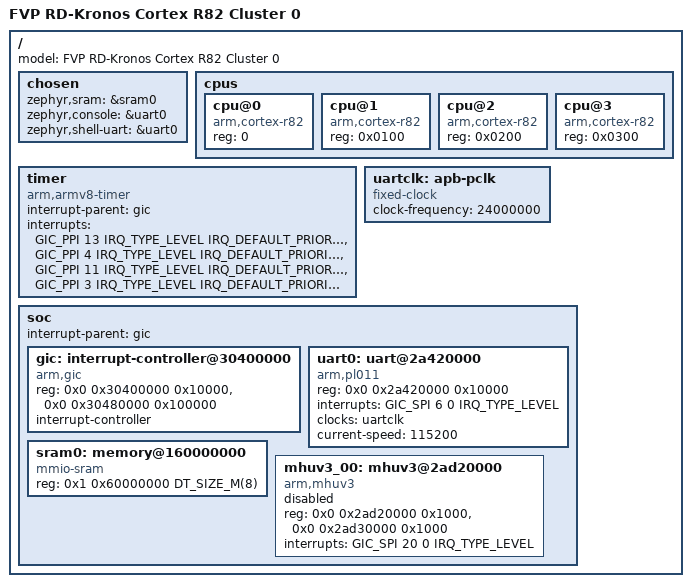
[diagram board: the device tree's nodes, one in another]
/*
 * SPDX-FileCopyrightText: <text>Copyright 2023 Arm Limited and/or its
 * affiliates <open-source-office@arm.com></text>
 *
 * SPDX-License-Identifier: Apache-2.0
 */

/dts-v1/;

#include <mem.h>
#include <arm64/armv8-r.dtsi>
#include <dt-bindings/interrupt-controller/arm-gic.h>
#include "fvp_rd_kronos_cortex_r82_device_mem.dtsi"

/ {
	#address-cells = <2>;
	#size-cells = <1>;
	model = "FVP RD-Kronos Cortex R82 Cluster 0";

	chosen {
		zephyr,sram = &sram0;
		zephyr,console = &uart0;
		zephyr,shell-uart = &uart0;
	};

	cpus {
		#address-cells = <1>;
		#size-cells = <0>;

		cpu@0 {
			device_type = "cpu";
			compatible = "arm,cortex-r82";
			reg = <0>;
		};

		cpu@1 {
			device_type = "cpu";
			compatible = "arm,cortex-r82";
			reg = <0x0100>;
		};

		cpu@2 {
			device_type = "cpu";
			compatible = "arm,cortex-r82";
			reg = <0x0200>;
		};

		cpu@3 {
			device_type = "cpu";
			compatible = "arm,cortex-r82";
			reg = <0x0300>;
		};

	};

	timer {
		compatible = "arm,armv8-timer";
		interrupt-parent = <&gic>;
		interrupts = <GIC_PPI 13 IRQ_TYPE_LEVEL
			      IRQ_DEFAULT_PRIORITY>,
			     <GIC_PPI 4 IRQ_TYPE_LEVEL
			      IRQ_DEFAULT_PRIORITY>,
			     <GIC_PPI 11 IRQ_TYPE_LEVEL
			      IRQ_DEFAULT_PRIORITY>,
			     <GIC_PPI 3 IRQ_TYPE_LEVEL
			      IRQ_DEFAULT_PRIORITY>;
	};

	uartclk: apb-pclk {
		compatible = "fixed-clock";
		clock-frequency = <24000000>;
		#clock-cells = <0>;
	};

	soc {
		#address-cells = <2>;
		#size-cells = <1>;
		interrupt-parent = <&gic>;

		gic: interrupt-controller@30400000 {
			compatible = "arm,gic";
			reg = <0x0 0x30400000 0x10000>,
			      <0x0 0x30480000 0x100000>;
			interrupt-controller;
			#interrupt-cells = <4>;
			status = "okay";
		};

		uart0: uart@2a420000 {
			compatible = "arm,pl011";
			reg = <0x0 0x2a420000 0x10000>;
			status = "disabled";
			interrupts = <GIC_SPI 6 0 IRQ_TYPE_LEVEL>;
			interrupt-names = "irq_0";
			clocks = <&uartclk>;
		};

		sram0: memory@160000000 {
			compatible = "mmio-sram";
			reg = <0x1 0x60000000 DT_SIZE_M(8)>;
		};

		mhuv3_00: mhuv3@2ad20000 {
			compatible = "arm,mhuv3";
			reg = <0x0 0x2ad20000 0x1000>,
			      <0x0 0x2ad30000 0x1000>;
			reg-names = "tx", "rx";
			interrupts = <GIC_SPI 20 0 IRQ_TYPE_LEVEL>;
			interrupt-names = "rx";
			status = "disabled";
		};
	};
};

&uart0 {
	status = "okay";
	current-speed = <115200>;
};
